AUTOSAR XML (schema 4-2-2)
package /STELLANTIS/EPT/COMSWCs
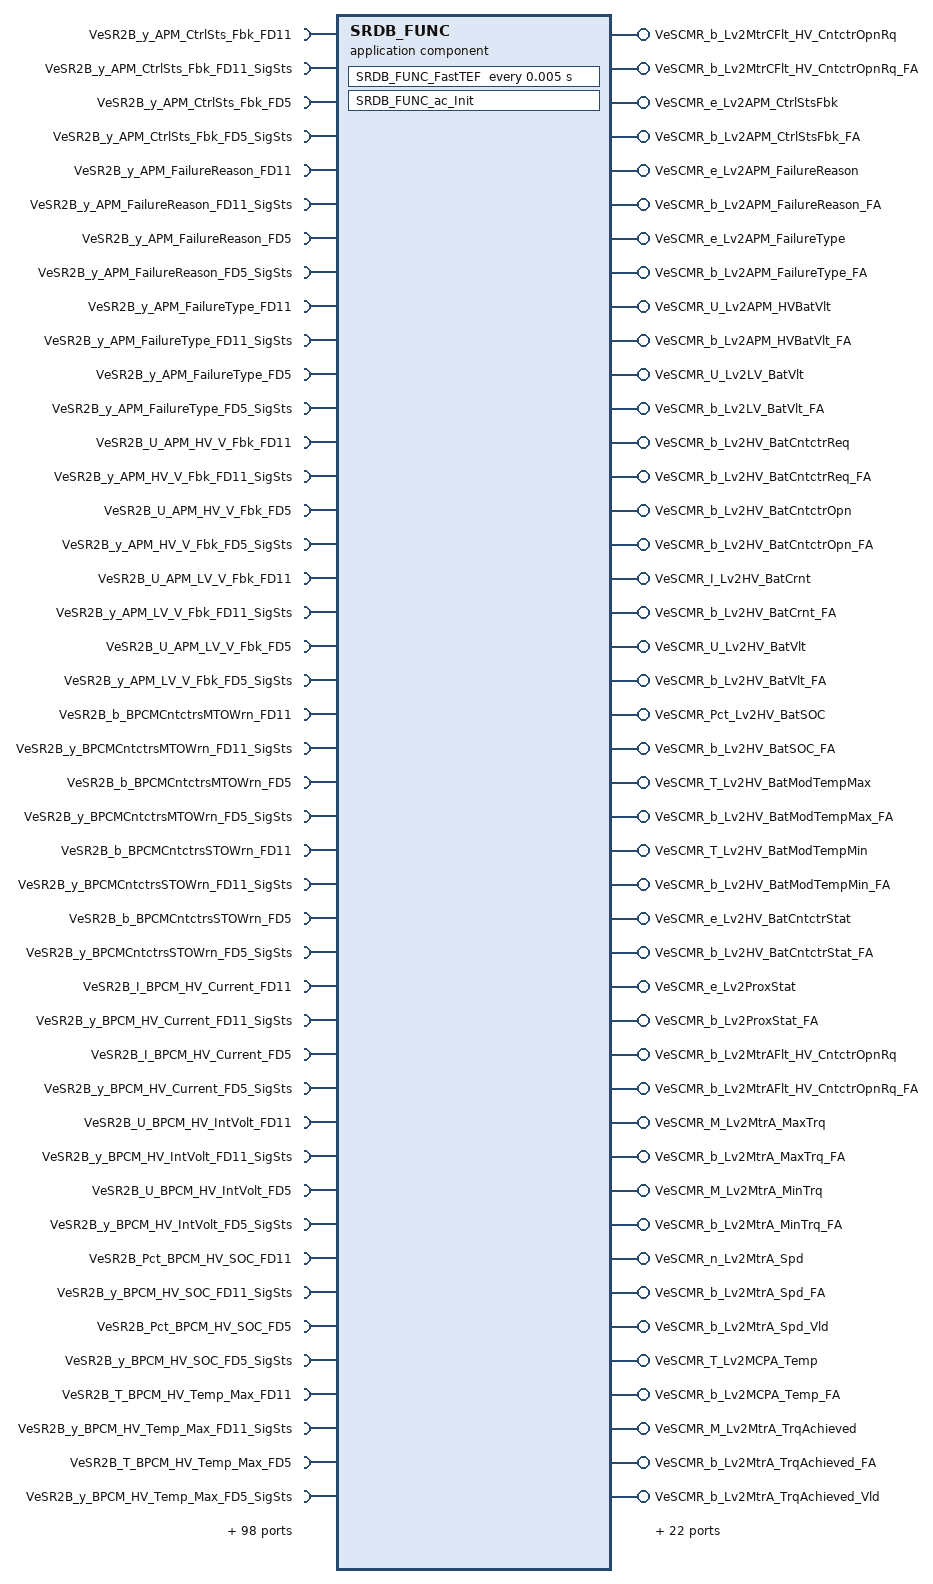
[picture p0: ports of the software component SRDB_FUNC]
  application sw component type SRDB_FUNC
    140 x require port:
      VeSR2B_y_APM_CtrlSts_Fbk_FD11: nonqueued-receiver-com-spec{data-element=Value, handle-never-received=true, init-value=0}, required-interface=VeSR2B_y_APM_CtrlSts_Fbk_FD11
      VeSR2B_y_APM_CtrlSts_Fbk_FD11_SigSts: nonqueued-receiver-com-spec{data-element=Value, init-value=0}, required-interface=VeSR2B_y_APM_CtrlSts_Fbk_FD11_SigSts
      VeSR2B_y_APM_CtrlSts_Fbk_FD5: nonqueued-receiver-com-spec{data-element=Value, handle-never-received=true, init-value=0}, required-interface=VeSR2B_y_APM_CtrlSts_Fbk_FD5
      VeSR2B_y_APM_CtrlSts_Fbk_FD5_SigSts: nonqueued-receiver-com-spec{data-element=Value, init-value=0}, required-interface=VeSR2B_y_APM_CtrlSts_Fbk_FD5_SigSts
      VeSR2B_y_APM_FailureReason_FD11: nonqueued-receiver-com-spec{data-element=Value, handle-never-received=true, init-value=0}, required-interface=VeSR2B_y_APM_FailureReason_FD11
      VeSR2B_y_APM_FailureReason_FD11_SigSts: nonqueued-receiver-com-spec{data-element=Value, init-value=0}, required-interface=VeSR2B_y_APM_FailureReason_FD11_SigSts
      VeSR2B_y_APM_FailureReason_FD5: nonqueued-receiver-com-spec{data-element=Value, handle-never-received=true, init-value=0}, required-interface=VeSR2B_y_APM_FailureReason_FD5
      VeSR2B_y_APM_FailureReason_FD5_SigSts: nonqueued-receiver-com-spec{data-element=Value, init-value=0}, required-interface=VeSR2B_y_APM_FailureReason_FD5_SigSts
      VeSR2B_y_APM_FailureType_FD11: nonqueued-receiver-com-spec{data-element=Value, handle-never-received=true, init-value=0}, required-interface=VeSR2B_y_APM_FailureType_FD11
      VeSR2B_y_APM_FailureType_FD11_SigSts: nonqueued-receiver-com-spec{data-element=Value, init-value=0}, required-interface=VeSR2B_y_APM_FailureType_FD11_SigSts
      VeSR2B_y_APM_FailureType_FD5: nonqueued-receiver-com-spec{data-element=Value, handle-never-received=true, init-value=0}, required-interface=VeSR2B_y_APM_FailureType_FD5
      VeSR2B_y_APM_FailureType_FD5_SigSts: nonqueued-receiver-com-spec{data-element=Value, init-value=0}, required-interface=VeSR2B_y_APM_FailureType_FD5_SigSts
      VeSR2B_U_APM_HV_V_Fbk_FD11: nonqueued-receiver-com-spec{data-element=Value, handle-never-received=true, init-value=0}, required-interface=VeSR2B_U_APM_HV_V_Fbk_FD11
      VeSR2B_y_APM_HV_V_Fbk_FD11_SigSts: nonqueued-receiver-com-spec{data-element=Value, init-value=0}, required-interface=VeSR2B_y_APM_HV_V_Fbk_FD11_SigSts
      VeSR2B_U_APM_HV_V_Fbk_FD5: nonqueued-receiver-com-spec{data-element=Value, handle-never-received=true, init-value=0}, required-interface=VeSR2B_U_APM_HV_V_Fbk_FD5
      VeSR2B_y_APM_HV_V_Fbk_FD5_SigSts: nonqueued-receiver-com-spec{data-element=Value, init-value=0}, required-interface=VeSR2B_y_APM_HV_V_Fbk_FD5_SigSts
      VeSR2B_U_APM_LV_V_Fbk_FD11: nonqueued-receiver-com-spec{data-element=Value, handle-never-received=true, init-value=0}, required-interface=VeSR2B_U_APM_LV_V_Fbk_FD11
      VeSR2B_y_APM_LV_V_Fbk_FD11_SigSts: nonqueued-receiver-com-spec{data-element=Value, init-value=0}, required-interface=VeSR2B_y_APM_LV_V_Fbk_FD11_SigSts
      VeSR2B_U_APM_LV_V_Fbk_FD5: nonqueued-receiver-com-spec{data-element=Value, handle-never-received=true, init-value=0}, required-interface=VeSR2B_U_APM_LV_V_Fbk_FD5
      VeSR2B_y_APM_LV_V_Fbk_FD5_SigSts: nonqueued-receiver-com-spec{data-element=Value, init-value=0}, required-interface=VeSR2B_y_APM_LV_V_Fbk_FD5_SigSts
      VeSR2B_b_BPCMCntctrsMTOWrn_FD11: nonqueued-receiver-com-spec{data-element=Value, handle-never-received=true, init-value=0}, required-interface=VeSR2B_b_BPCMCntctrsMTOWrn_FD11
      VeSR2B_y_BPCMCntctrsMTOWrn_FD11_SigSts: nonqueued-receiver-com-spec{data-element=Value, init-value=0}, required-interface=VeSR2B_y_BPCMCntctrsMTOWrn_FD11_SigSts
      VeSR2B_b_BPCMCntctrsMTOWrn_FD5: nonqueued-receiver-com-spec{data-element=Value, handle-never-received=true, init-value=0}, required-interface=VeSR2B_b_BPCMCntctrsMTOWrn_FD5
      VeSR2B_y_BPCMCntctrsMTOWrn_FD5_SigSts: nonqueued-receiver-com-spec{data-element=Value, init-value=0}, required-interface=VeSR2B_y_BPCMCntctrsMTOWrn_FD5_SigSts
      VeSR2B_b_BPCMCntctrsSTOWrn_FD11: nonqueued-receiver-com-spec{data-element=Value, handle-never-received=true, init-value=0}, required-interface=VeSR2B_b_BPCMCntctrsSTOWrn_FD11
      VeSR2B_y_BPCMCntctrsSTOWrn_FD11_SigSts: nonqueued-receiver-com-spec{data-element=Value, init-value=0}, required-interface=VeSR2B_y_BPCMCntctrsSTOWrn_FD11_SigSts
      VeSR2B_b_BPCMCntctrsSTOWrn_FD5: nonqueued-receiver-com-spec{data-element=Value, handle-never-received=true, init-value=0}, required-interface=VeSR2B_b_BPCMCntctrsSTOWrn_FD5
      VeSR2B_y_BPCMCntctrsSTOWrn_FD5_SigSts: nonqueued-receiver-com-spec{data-element=Value, init-value=0}, required-interface=VeSR2B_y_BPCMCntctrsSTOWrn_FD5_SigSts
      VeSR2B_I_BPCM_HV_Current_FD11: nonqueued-receiver-com-spec{data-element=Value, handle-never-received=true, init-value=0}, required-interface=VeSR2B_I_BPCM_HV_Current_FD11
      VeSR2B_y_BPCM_HV_Current_FD11_SigSts: nonqueued-receiver-com-spec{data-element=Value, init-value=0}, required-interface=VeSR2B_y_BPCM_HV_Current_FD11_SigSts
      VeSR2B_I_BPCM_HV_Current_FD5: nonqueued-receiver-com-spec{data-element=Value, handle-never-received=true, init-value=0}, required-interface=VeSR2B_I_BPCM_HV_Current_FD5
      VeSR2B_y_BPCM_HV_Current_FD5_SigSts: nonqueued-receiver-com-spec{data-element=Value, init-value=0}, required-interface=VeSR2B_y_BPCM_HV_Current_FD5_SigSts
      VeSR2B_U_BPCM_HV_IntVolt_FD11: nonqueued-receiver-com-spec{data-element=Value, handle-never-received=true, init-value=0}, required-interface=VeSR2B_U_BPCM_HV_IntVolt_FD11
      VeSR2B_y_BPCM_HV_IntVolt_FD11_SigSts: nonqueued-receiver-com-spec{data-element=Value, init-value=0}, required-interface=VeSR2B_y_BPCM_HV_IntVolt_FD11_SigSts
      VeSR2B_U_BPCM_HV_IntVolt_FD5: nonqueued-receiver-com-spec{data-element=Value, handle-never-received=true, init-value=0}, required-interface=VeSR2B_U_BPCM_HV_IntVolt_FD5
      VeSR2B_y_BPCM_HV_IntVolt_FD5_SigSts: nonqueued-receiver-com-spec{data-element=Value, init-value=0}, required-interface=VeSR2B_y_BPCM_HV_IntVolt_FD5_SigSts
      VeSR2B_Pct_BPCM_HV_SOC_FD11: nonqueued-receiver-com-spec{data-element=Value, handle-never-received=true, init-value=0}, required-interface=VeSR2B_Pct_BPCM_HV_SOC_FD11
      VeSR2B_y_BPCM_HV_SOC_FD11_SigSts: nonqueued-receiver-com-spec{data-element=Value, init-value=0}, required-interface=VeSR2B_y_BPCM_HV_SOC_FD11_SigSts
      VeSR2B_Pct_BPCM_HV_SOC_FD5: nonqueued-receiver-com-spec{data-element=Value, handle-never-received=true, init-value=0}, required-interface=VeSR2B_Pct_BPCM_HV_SOC_FD5
      VeSR2B_y_BPCM_HV_SOC_FD5_SigSts: nonqueued-receiver-com-spec{data-element=Value, init-value=0}, required-interface=VeSR2B_y_BPCM_HV_SOC_FD5_SigSts
      VeSR2B_T_BPCM_HV_Temp_Max_FD11: nonqueued-receiver-com-spec{data-element=Value, handle-never-received=true, init-value=0}, required-interface=VeSR2B_T_BPCM_HV_Temp_Max_FD11
      VeSR2B_y_BPCM_HV_Temp_Max_FD11_SigSts: nonqueued-receiver-com-spec{data-element=Value, init-value=0}, required-interface=VeSR2B_y_BPCM_HV_Temp_Max_FD11_SigSts
      VeSR2B_T_BPCM_HV_Temp_Max_FD5: nonqueued-receiver-com-spec{data-element=Value, handle-never-received=true, init-value=0}, required-interface=VeSR2B_T_BPCM_HV_Temp_Max_FD5
      VeSR2B_y_BPCM_HV_Temp_Max_FD5_SigSts: nonqueued-receiver-com-spec{data-element=Value, init-value=0}, required-interface=VeSR2B_y_BPCM_HV_Temp_Max_FD5_SigSts
      VeSR2B_T_BPCM_HV_Temp_Min_FD11: nonqueued-receiver-com-spec{data-element=Value, handle-never-received=true, init-value=0}, required-interface=VeSR2B_T_BPCM_HV_Temp_Min_FD11
      VeSR2B_y_BPCM_HV_Temp_Min_FD11_SigSts: nonqueued-receiver-com-spec{data-element=Value, init-value=0}, required-interface=VeSR2B_y_BPCM_HV_Temp_Min_FD11_SigSts
      VeSR2B_T_BPCM_HV_Temp_Min_FD5: nonqueued-receiver-com-spec{data-element=Value, handle-never-received=true, init-value=0}, required-interface=VeSR2B_T_BPCM_HV_Temp_Min_FD5
      VeSR2B_y_BPCM_HV_Temp_Min_FD5_SigSts: nonqueued-receiver-com-spec{data-element=Value, init-value=0}, required-interface=VeSR2B_y_BPCM_HV_Temp_Min_FD5_SigSts
      VeSR2B_y_BPCM_HV_TracBusStsFD11: nonqueued-receiver-com-spec{data-element=Value, handle-never-received=true, init-value=0}, required-interface=VeSR2B_y_BPCM_HV_TracBusStsFD11
      VeSR2B_y_BPCM_HV_TracBusStsFD11_SigSts: nonqueued-receiver-com-spec{data-element=Value, init-value=0}, required-interface=VeSR2B_y_BPCM_HV_TracBusStsFD11_SigSts
      VeSR2B_y_BPCM_HV_TracBusStsFD5: nonqueued-receiver-com-spec{data-element=Value, handle-never-received=true, init-value=0}, required-interface=VeSR2B_y_BPCM_HV_TracBusStsFD5
      VeSR2B_y_BPCM_HV_TracBusStsFD5_SigSts: nonqueued-receiver-com-spec{data-element=Value, init-value=0}, required-interface=VeSR2B_y_BPCM_HV_TracBusStsFD5_SigSts
      VeSR2B_y_ProximitySts_FD11: nonqueued-receiver-com-spec{data-element=Value, handle-never-received=true, init-value=0}, required-interface=VeSR2B_y_ProximitySts_FD11
      VeSR2B_y_ProximitySts_FD11_SigSts: nonqueued-receiver-com-spec{data-element=Value, init-value=0}, required-interface=VeSR2B_y_ProximitySts_FD11_SigSts
      VeSR2B_y_ProximitySts_FD5: nonqueued-receiver-com-spec{data-element=Value, handle-never-received=true, init-value=0}, required-interface=VeSR2B_y_ProximitySts_FD5
      VeSR2B_y_ProximitySts_FD5_SigSts: nonqueued-receiver-com-spec{data-element=Value, init-value=0}, required-interface=VeSR2B_y_ProximitySts_FD5_SigSts
      VeSR2B_b_MCPA_HV_CnctrOpn_Req_P_FD16: nonqueued-receiver-com-spec{data-element=Value, handle-never-received=true, init-value=0}, required-interface=VeSR2B_b_MCPA_HV_CnctrOpn_Req_P_FD16
      VeSR2B_y_MCPA_HV_CnctrOpn_Req_P_FD16_SigSts: nonqueued-receiver-com-spec{data-element=Value, init-value=0}, required-interface=VeSR2B_y_MCPA_HV_CnctrOpn_Req_P_FD16_SigSts
      VeSR2B_b_MCPA_HV_CnctrOpnRqPFD5: nonqueued-receiver-com-spec{data-element=Value, handle-never-received=true, init-value=0}, required-interface=VeSR2B_b_MCPA_HV_CnctrOpnRqPFD5
      VeSR2B_y_MCPA_HV_CnctrOpnRqPFD5_SigSts: nonqueued-receiver-com-spec{data-element=Value, init-value=0}, required-interface=VeSR2B_y_MCPA_HV_CnctrOpnRqPFD5_SigSts
      VeSR2B_M_MCPA_MaxTorq_P_FD16: nonqueued-receiver-com-spec{data-element=Value, handle-never-received=true, init-value=0}, required-interface=VeSR2B_M_MCPA_MaxTorq_P_FD16
      VeSR2B_y_MCPA_MaxTorq_P_FD16_SigSts: nonqueued-receiver-com-spec{data-element=Value, init-value=0}, required-interface=VeSR2B_y_MCPA_MaxTorq_P_FD16_SigSts
      VeSR2B_M_MCPA_MaxTorq_P_FD5: nonqueued-receiver-com-spec{data-element=Value, handle-never-received=true, init-value=0}, required-interface=VeSR2B_M_MCPA_MaxTorq_P_FD5
      VeSR2B_y_MCPA_MaxTorq_P_FD5_SigSts: nonqueued-receiver-com-spec{data-element=Value, init-value=0}, required-interface=VeSR2B_y_MCPA_MaxTorq_P_FD5_SigSts
      VeSR2B_M_MCPA_MinTorq_P_FD16: nonqueued-receiver-com-spec{data-element=Value, handle-never-received=true, init-value=0}, required-interface=VeSR2B_M_MCPA_MinTorq_P_FD16
      VeSR2B_y_MCPA_MinTorq_P_FD16_SigSts: nonqueued-receiver-com-spec{data-element=Value, init-value=0}, required-interface=VeSR2B_y_MCPA_MinTorq_P_FD16_SigSts
      VeSR2B_M_MCPA_MinTorq_P_FD5: nonqueued-receiver-com-spec{data-element=Value, handle-never-received=true, init-value=0}, required-interface=VeSR2B_M_MCPA_MinTorq_P_FD5
      VeSR2B_y_MCPA_MinTorq_P_FD5_SigSts: nonqueued-receiver-com-spec{data-element=Value, init-value=0}, required-interface=VeSR2B_y_MCPA_MinTorq_P_FD5_SigSts
      VeSR2B_n_MCPA_RPM_P_FD16: nonqueued-receiver-com-spec{data-element=Value, handle-never-received=true, init-value=0}, required-interface=VeSR2B_n_MCPA_RPM_P_FD16
      VeSR2B_y_MCPA_RPM_P_FD16_SigSts: nonqueued-receiver-com-spec{data-element=Value, init-value=0}, required-interface=VeSR2B_y_MCPA_RPM_P_FD16_SigSts
      VeSR2B_n_MCPA_RPM_P_FD5: nonqueued-receiver-com-spec{data-element=Value, handle-never-received=true, init-value=0}, required-interface=VeSR2B_n_MCPA_RPM_P_FD5
      VeSR2B_y_MCPA_RPM_P_FD5_SigSts: nonqueued-receiver-com-spec{data-element=Value, init-value=0}, required-interface=VeSR2B_y_MCPA_RPM_P_FD5_SigSts
      VeSR2B_b_MCPA_RPM_V_P_FD16: nonqueued-receiver-com-spec{data-element=Value, handle-never-received=true, init-value=0}, required-interface=VeSR2B_b_MCPA_RPM_V_P_FD16
      VeSR2B_y_MCPA_RPM_V_P_FD16_SigSts: nonqueued-receiver-com-spec{data-element=Value, init-value=0}, required-interface=VeSR2B_y_MCPA_RPM_V_P_FD16_SigSts
      VeSR2B_b_MCPA_RPM_V_P_FD5: nonqueued-receiver-com-spec{data-element=Value, handle-never-received=true, init-value=0}, required-interface=VeSR2B_b_MCPA_RPM_V_P_FD5
      VeSR2B_y_MCPA_RPM_V_P_FD5_SigSts: nonqueued-receiver-com-spec{data-element=Value, init-value=0}, required-interface=VeSR2B_y_MCPA_RPM_V_P_FD5_SigSts
      VeSR2B_T_MCPA_Temp_P_FD16: nonqueued-receiver-com-spec{data-element=Value, handle-never-received=true, init-value=0}, required-interface=VeSR2B_T_MCPA_Temp_P_FD16
      VeSR2B_y_MCPA_Temp_P_FD16_SigSts: nonqueued-receiver-com-spec{data-element=Value, init-value=0}, required-interface=VeSR2B_y_MCPA_Temp_P_FD16_SigSts
      VeSR2B_T_MCPA_Temp_P_FD5: nonqueued-receiver-com-spec{data-element=Value, handle-never-received=true, init-value=0}, required-interface=VeSR2B_T_MCPA_Temp_P_FD5
      VeSR2B_y_MCPA_Temp_P_FD5_SigSts: nonqueued-receiver-com-spec{data-element=Value, init-value=0}, required-interface=VeSR2B_y_MCPA_Temp_P_FD5_SigSts
      VeSR2B_M_MCPA_TorqAchved_AEMD_P_FD16: nonqueued-receiver-com-spec{data-element=Value, handle-never-received=true, init-value=0}, required-interface=VeSR2B_M_MCPA_TorqAchved_AEMD_P_FD16
      VeSR2B_y_MCPA_TorqAchved_AEMD_P_FD16_SigSts: nonqueued-receiver-com-spec{data-element=Value, init-value=0}, required-interface=VeSR2B_y_MCPA_TorqAchved_AEMD_P_FD16_SigSts
      VeSR2B_M_MCPA_TrqAchvdAEMDPFD5: nonqueued-receiver-com-spec{data-element=Value, handle-never-received=true, init-value=0}, required-interface=VeSR2B_M_MCPA_TrqAchvdAEMDPFD5
      VeSR2B_y_MCPA_TrqAchvdAEMDPFD5_SigSts: nonqueued-receiver-com-spec{data-element=Value, init-value=0}, required-interface=VeSR2B_y_MCPA_TrqAchvdAEMDPFD5_SigSts
      VeSR2B_b_MCPA_TrqAchvd_AEMD_V_P_FD16: nonqueued-receiver-com-spec{data-element=Value, handle-never-received=true, init-value=0}, required-interface=VeSR2B_b_MCPA_TrqAchvd_AEMD_V_P_FD16
      VeSR2B_y_MCPA_TrqAchvd_AEMD_V_P_FD16_SigSts: nonqueued-receiver-com-spec{data-element=Value, init-value=0}, required-interface=VeSR2B_y_MCPA_TrqAchvd_AEMD_V_P_FD16_SigSts
      VeSR2B_b_MCPA_TrqAchvdAEMDVPFD5: nonqueued-receiver-com-spec{data-element=Value, handle-never-received=true, init-value=0}, required-interface=VeSR2B_b_MCPA_TrqAchvdAEMDVPFD5
      VeSR2B_y_MCPA_TrqAchvdAEMDVPFD5_SigSts: nonqueued-receiver-com-spec{data-element=Value, init-value=0}, required-interface=VeSR2B_y_MCPA_TrqAchvdAEMDVPFD5_SigSts
      VeSR2B_M_MCPA_Torque_Achieved_P_FD16: nonqueued-receiver-com-spec{data-element=Value, handle-never-received=true, init-value=0}, required-interface=VeSR2B_M_MCPA_Torque_Achieved_P_FD16
      VeSR2B_y_MCPA_Torque_Achieved_P_FD16_SigSts: nonqueued-receiver-com-spec{data-element=Value, init-value=0}, required-interface=VeSR2B_y_MCPA_Torque_Achieved_P_FD16_SigSts
      VeSR2B_M_MCPA_Torque_AchvdPFD5: nonqueued-receiver-com-spec{data-element=Value, handle-never-received=true, init-value=0}, required-interface=VeSR2B_M_MCPA_Torque_AchvdPFD5
      VeSR2B_y_MCPA_Torque_AchvdPFD5_SigSts: nonqueued-receiver-com-spec{data-element=Value, init-value=0}, required-interface=VeSR2B_y_MCPA_Torque_AchvdPFD5_SigSts
      VeSR2B_b_MCPA_Torque_Achved_V_P_FD16: nonqueued-receiver-com-spec{data-element=Value, handle-never-received=true, init-value=0}, required-interface=VeSR2B_b_MCPA_Torque_Achved_V_P_FD16
      VeSR2B_y_MCPA_Torque_Achved_V_P_FD16_SigSts: nonqueued-receiver-com-spec{data-element=Value, init-value=0}, required-interface=VeSR2B_y_MCPA_Torque_Achved_V_P_FD16_SigSts
      VeSR2B_b_MCPA_Trque_AchvdVPFD5: nonqueued-receiver-com-spec{data-element=Value, handle-never-received=true, init-value=0}, required-interface=VeSR2B_b_MCPA_Trque_AchvdVPFD5
      VeSR2B_y_MCPA_Trque_AchvdVPFD5_SigSts: nonqueued-receiver-com-spec{data-element=Value, init-value=0}, required-interface=VeSR2B_y_MCPA_Trque_AchvdVPFD5_SigSts
      VeSR2B_b_MCPB_HV_CnctrOpn_Req_P_FD16: nonqueued-receiver-com-spec{data-element=Value, handle-never-received=true, init-value=0}, required-interface=VeSR2B_b_MCPB_HV_CnctrOpn_Req_P_FD16
      VeSR2B_y_MCPB_HV_CnctrOpn_Req_P_FD16_SigSts: nonqueued-receiver-com-spec{data-element=Value, init-value=0}, required-interface=VeSR2B_y_MCPB_HV_CnctrOpn_Req_P_FD16_SigSts
      VeSR2B_b_MCPB_HV_CnctrOpnRqPFD5: nonqueued-receiver-com-spec{data-element=Value, handle-never-received=true, init-value=0}, required-interface=VeSR2B_b_MCPB_HV_CnctrOpnRqPFD5
      VeSR2B_y_MCPB_HV_CnctrOpnRqPFD5_SigSts: nonqueued-receiver-com-spec{data-element=Value, init-value=0}, required-interface=VeSR2B_y_MCPB_HV_CnctrOpnRqPFD5_SigSts
      VeSR2B_M_MCPB_MaxTorq_P_FD16: nonqueued-receiver-com-spec{data-element=Value, handle-never-received=true, init-value=0}, required-interface=VeSR2B_M_MCPB_MaxTorq_P_FD16
      VeSR2B_y_MCPB_MaxTorq_P_FD16_SigSts: nonqueued-receiver-com-spec{data-element=Value, init-value=0}, required-interface=VeSR2B_y_MCPB_MaxTorq_P_FD16_SigSts
      VeSR2B_M_MCPB_MaxTorq_P_FD5: nonqueued-receiver-com-spec{data-element=Value, handle-never-received=true, init-value=0}, required-interface=VeSR2B_M_MCPB_MaxTorq_P_FD5
      VeSR2B_y_MCPB_MaxTorq_P_FD5_SigSts: nonqueued-receiver-com-spec{data-element=Value, init-value=0}, required-interface=VeSR2B_y_MCPB_MaxTorq_P_FD5_SigSts
      VeSR2B_M_MCPB_MinTorq_P_FD16: nonqueued-receiver-com-spec{data-element=Value, handle-never-received=true, init-value=0}, required-interface=VeSR2B_M_MCPB_MinTorq_P_FD16
      VeSR2B_y_MCPB_MinTorq_P_FD16_SigSts: nonqueued-receiver-com-spec{data-element=Value, init-value=0}, required-interface=VeSR2B_y_MCPB_MinTorq_P_FD16_SigSts
      VeSR2B_M_MCPB_MinTorq_P_FD5: nonqueued-receiver-com-spec{data-element=Value, handle-never-received=true, init-value=0}, required-interface=VeSR2B_M_MCPB_MinTorq_P_FD5
      VeSR2B_y_MCPB_MinTorq_P_FD5_SigSts: nonqueued-receiver-com-spec{data-element=Value, init-value=0}, required-interface=VeSR2B_y_MCPB_MinTorq_P_FD5_SigSts
      VeSR2B_y_MCPB_MtrIndex_P_FD16: nonqueued-receiver-com-spec{data-element=Value, handle-never-received=true, init-value=0}, required-interface=VeSR2B_y_MCPB_MtrIndex_P_FD16
      VeSR2B_y_MCPB_MtrIndex_P_FD16_SigSts: nonqueued-receiver-com-spec{data-element=Value, init-value=0}, required-interface=VeSR2B_y_MCPB_MtrIndex_P_FD16_SigSts
      VeSR2B_y_MCPB_MtrIndex_P_FD5: nonqueued-receiver-com-spec{data-element=Value, handle-never-received=true, init-value=0}, required-interface=VeSR2B_y_MCPB_MtrIndex_P_FD5
      VeSR2B_y_MCPB_MtrIndex_P_FD5_SigSts: nonqueued-receiver-com-spec{data-element=Value, init-value=0}, required-interface=VeSR2B_y_MCPB_MtrIndex_P_FD5_SigSts
      VeSR2B_n_MCPB_RPM_P_FD16: nonqueued-receiver-com-spec{data-element=Value, handle-never-received=true, init-value=0}, required-interface=VeSR2B_n_MCPB_RPM_P_FD16
      VeSR2B_y_MCPB_RPM_P_FD16_SigSts: nonqueued-receiver-com-spec{data-element=Value, init-value=0}, required-interface=VeSR2B_y_MCPB_RPM_P_FD16_SigSts
      VeSR2B_n_MCPB_RPM_P_FD5: nonqueued-receiver-com-spec{data-element=Value, handle-never-received=true, init-value=0}, required-interface=VeSR2B_n_MCPB_RPM_P_FD5
      VeSR2B_y_MCPB_RPM_P_FD5_SigSts: nonqueued-receiver-com-spec{data-element=Value, init-value=0}, required-interface=VeSR2B_y_MCPB_RPM_P_FD5_SigSts
      VeSR2B_b_MCPB_RPM_V_P_FD16: nonqueued-receiver-com-spec{data-element=Value, handle-never-received=true, init-value=0}, required-interface=VeSR2B_b_MCPB_RPM_V_P_FD16
      VeSR2B_y_MCPB_RPM_V_P_FD16_SigSts: nonqueued-receiver-com-spec{data-element=Value, init-value=0}, required-interface=VeSR2B_y_MCPB_RPM_V_P_FD16_SigSts
      VeSR2B_b_MCPB_RPM_V_P_FD5: nonqueued-receiver-com-spec{data-element=Value, handle-never-received=true, init-value=0}, required-interface=VeSR2B_b_MCPB_RPM_V_P_FD5
      VeSR2B_y_MCPB_RPM_V_P_FD5_SigSts: nonqueued-receiver-com-spec{data-element=Value, init-value=0}, required-interface=VeSR2B_y_MCPB_RPM_V_P_FD5_SigSts
      VeSR2B_y_MCPB_Temp_P_FD16: nonqueued-receiver-com-spec{data-element=Value, handle-never-received=true, init-value=0}, required-interface=VeSR2B_y_MCPB_Temp_P_FD16
      VeSR2B_y_MCPB_Temp_P_FD16_SigSts: nonqueued-receiver-com-spec{data-element=Value, init-value=0}, required-interface=VeSR2B_y_MCPB_Temp_P_FD16_SigSts
      VeSR2B_y_MCPB_Temp_P_FD5: nonqueued-receiver-com-spec{data-element=Value, handle-never-received=true, init-value=0}, required-interface=VeSR2B_y_MCPB_Temp_P_FD5
      VeSR2B_y_MCPB_Temp_P_FD5_SigSts: nonqueued-receiver-com-spec{data-element=Value, init-value=0}, required-interface=VeSR2B_y_MCPB_Temp_P_FD5_SigSts
      VeSR2B_M_MCPB_TorqAchved_AEMD_P_FD16: nonqueued-receiver-com-spec{data-element=Value, handle-never-received=true, init-value=0}, required-interface=VeSR2B_M_MCPB_TorqAchved_AEMD_P_FD16
      VeSR2B_y_MCPB_TorqAchved_AEMD_P_FD16_SigSts: nonqueued-receiver-com-spec{data-element=Value, init-value=0}, required-interface=VeSR2B_y_MCPB_TorqAchved_AEMD_P_FD16_SigSts
      VeSR2B_M_MCPB_TrqAchvd_AEMDPFD5: nonqueued-receiver-com-spec{data-element=Value, handle-never-received=true, init-value=0}, required-interface=VeSR2B_M_MCPB_TrqAchvd_AEMDPFD5
      VeSR2B_y_MCPB_TrqAchvd_AEMDPFD5_SigSts: nonqueued-receiver-com-spec{data-element=Value, init-value=0}, required-interface=VeSR2B_y_MCPB_TrqAchvd_AEMDPFD5_SigSts
      VeSR2B_b_MCPB_TrqAchvd_AEMD_V_P_FD16: nonqueued-receiver-com-spec{data-element=Value, handle-never-received=true, init-value=0}, required-interface=VeSR2B_b_MCPB_TrqAchvd_AEMD_V_P_FD16
      VeSR2B_y_MCPB_TrqAchvd_AEMD_V_P_FD16_SigSts: nonqueued-receiver-com-spec{data-element=Value, init-value=0}, required-interface=VeSR2B_y_MCPB_TrqAchvd_AEMD_V_P_FD16_SigSts
      VeSR2B_b_MCPB_TrqAchvdAEMDVPFD5: nonqueued-receiver-com-spec{data-element=Value, handle-never-received=true, init-value=0}, required-interface=VeSR2B_b_MCPB_TrqAchvdAEMDVPFD5
      VeSR2B_y_MCPB_TrqAchvdAEMDVPFD5_SigSts: nonqueued-receiver-com-spec{data-element=Value, init-value=0}, required-interface=VeSR2B_y_MCPB_TrqAchvdAEMDVPFD5_SigSts
      VeSR2B_M_MCPB_Torque_Achieved_P_FD16: nonqueued-receiver-com-spec{data-element=Value, handle-never-received=true, init-value=0}, required-interface=VeSR2B_M_MCPB_Torque_Achieved_P_FD16
      VeSR2B_y_MCPB_Torque_Achieved_P_FD16_SigSts: nonqueued-receiver-com-spec{data-element=Value, init-value=0}, required-interface=VeSR2B_y_MCPB_Torque_Achieved_P_FD16_SigSts
      VeSR2B_M_MCPB_Trq_Achved_P_FD5: nonqueued-receiver-com-spec{data-element=Value, handle-never-received=true, init-value=0}, required-interface=VeSR2B_M_MCPB_Trq_Achved_P_FD5
      VeSR2B_y_MCPB_Trq_Achved_P_FD5_SigSts: nonqueued-receiver-com-spec{data-element=Value, init-value=0}, required-interface=VeSR2B_y_MCPB_Trq_Achved_P_FD5_SigSts
      VeSR2B_b_MCPB_Torque_Achved_V_P_FD16: nonqueued-receiver-com-spec{data-element=Value, handle-never-received=true, init-value=0}, required-interface=VeSR2B_b_MCPB_Torque_Achved_V_P_FD16
      VeSR2B_y_MCPB_Torque_Achved_V_P_FD16_SigSts: nonqueued-receiver-com-spec{data-element=Value, init-value=0}, required-interface=VeSR2B_y_MCPB_Torque_Achved_V_P_FD16_SigSts
      VeSR2B_b_MCPB_Trq_Achved_V_PFD5: nonqueued-receiver-com-spec{data-element=Value, handle-never-received=true, init-value=0}, required-interface=VeSR2B_b_MCPB_Trq_Achved_V_PFD5
      VeSR2B_y_MCPB_Trq_Achved_V_PFD5_SigSts: nonqueued-receiver-com-spec{data-element=Value, init-value=0}, required-interface=VeSR2B_y_MCPB_Trq_Achved_V_PFD5_SigSts
    66 x provide port:
      VeSCMR_b_Lv2MtrCFlt_HV_CntctrOpnRq: nonqueued-sender-com-spec{data-element=Value, init-value=0}, provided-interface=VeSCMR_b_Lv2MtrCFlt_HV_CntctrOpnRq
      VeSCMR_b_Lv2MtrCFlt_HV_CntctrOpnRq_FA: nonqueued-sender-com-spec{data-element=Value, init-value=0}, provided-interface=VeSCMR_b_Lv2MtrCFlt_HV_CntctrOpnRq_FA
      VeSCMR_e_Lv2APM_CtrlStsFbk: nonqueued-sender-com-spec{data-element=Value, init-value=0}, provided-interface=VeSCMR_e_Lv2APM_CtrlStsFbk
      VeSCMR_b_Lv2APM_CtrlStsFbk_FA: nonqueued-sender-com-spec{data-element=Value, init-value=0}, provided-interface=VeSCMR_b_Lv2APM_CtrlStsFbk_FA
      VeSCMR_e_Lv2APM_FailureReason: nonqueued-sender-com-spec{data-element=Value, init-value=0}, provided-interface=VeSCMR_e_Lv2APM_FailureReason
      VeSCMR_b_Lv2APM_FailureReason_FA: nonqueued-sender-com-spec{data-element=Value, init-value=0}, provided-interface=VeSCMR_b_Lv2APM_FailureReason_FA
      VeSCMR_e_Lv2APM_FailureType: nonqueued-sender-com-spec{data-element=Value, init-value=0}, provided-interface=VeSCMR_e_Lv2APM_FailureType
      VeSCMR_b_Lv2APM_FailureType_FA: nonqueued-sender-com-spec{data-element=Value, init-value=0}, provided-interface=VeSCMR_b_Lv2APM_FailureType_FA
      VeSCMR_U_Lv2APM_HVBatVlt: nonqueued-sender-com-spec{data-element=Value, init-value=0}, provided-interface=VeSCMR_U_Lv2APM_HVBatVlt
      VeSCMR_b_Lv2APM_HVBatVlt_FA: nonqueued-sender-com-spec{data-element=Value, init-value=0}, provided-interface=VeSCMR_b_Lv2APM_HVBatVlt_FA
      VeSCMR_U_Lv2LV_BatVlt: nonqueued-sender-com-spec{data-element=Value, init-value=0}, provided-interface=VeSCMR_U_Lv2LV_BatVlt
      VeSCMR_b_Lv2LV_BatVlt_FA: nonqueued-sender-com-spec{data-element=Value, init-value=0}, provided-interface=VeSCMR_b_Lv2LV_BatVlt_FA
      VeSCMR_b_Lv2HV_BatCntctrReq: nonqueued-sender-com-spec{data-element=Value, init-value=0}, provided-interface=VeSCMR_b_Lv2HV_BatCntctrReq
      VeSCMR_b_Lv2HV_BatCntctrReq_FA: nonqueued-sender-com-spec{data-element=Value, init-value=0}, provided-interface=VeSCMR_b_Lv2HV_BatCntctrReq_FA
      VeSCMR_b_Lv2HV_BatCntctrOpn: nonqueued-sender-com-spec{data-element=Value, init-value=0}, provided-interface=VeSCMR_b_Lv2HV_BatCntctrOpn
      VeSCMR_b_Lv2HV_BatCntctrOpn_FA: nonqueued-sender-com-spec{data-element=Value, init-value=0}, provided-interface=VeSCMR_b_Lv2HV_BatCntctrOpn_FA
      VeSCMR_I_Lv2HV_BatCrnt: nonqueued-sender-com-spec{data-element=Value, init-value=0}, provided-interface=VeSCMR_I_Lv2HV_BatCrnt
      VeSCMR_b_Lv2HV_BatCrnt_FA: nonqueued-sender-com-spec{data-element=Value, init-value=0}, provided-interface=VeSCMR_b_Lv2HV_BatCrnt_FA
      VeSCMR_U_Lv2HV_BatVlt: nonqueued-sender-com-spec{data-element=Value, init-value=0}, provided-interface=VeSCMR_U_Lv2HV_BatVlt
      VeSCMR_b_Lv2HV_BatVlt_FA: nonqueued-sender-com-spec{data-element=Value, init-value=0}, provided-interface=VeSCMR_b_Lv2HV_BatVlt_FA
      VeSCMR_Pct_Lv2HV_BatSOC: nonqueued-sender-com-spec{data-element=Value, init-value=0}, provided-interface=VeSCMR_Pct_Lv2HV_BatSOC
      VeSCMR_b_Lv2HV_BatSOC_FA: nonqueued-sender-com-spec{data-element=Value, init-value=0}, provided-interface=VeSCMR_b_Lv2HV_BatSOC_FA
      VeSCMR_T_Lv2HV_BatModTempMax: nonqueued-sender-com-spec{data-element=Value, init-value=0}, provided-interface=VeSCMR_T_Lv2HV_BatModTempMax
      VeSCMR_b_Lv2HV_BatModTempMax_FA: nonqueued-sender-com-spec{data-element=Value, init-value=0}, provided-interface=VeSCMR_b_Lv2HV_BatModTempMax_FA
      VeSCMR_T_Lv2HV_BatModTempMin: nonqueued-sender-com-spec{data-element=Value, init-value=0}, provided-interface=VeSCMR_T_Lv2HV_BatModTempMin
      VeSCMR_b_Lv2HV_BatModTempMin_FA: nonqueued-sender-com-spec{data-element=Value, init-value=0}, provided-interface=VeSCMR_b_Lv2HV_BatModTempMin_FA
      VeSCMR_e_Lv2HV_BatCntctrStat: nonqueued-sender-com-spec{data-element=Value, init-value=0}, provided-interface=VeSCMR_e_Lv2HV_BatCntctrStat
      VeSCMR_b_Lv2HV_BatCntctrStat_FA: nonqueued-sender-com-spec{data-element=Value, init-value=0}, provided-interface=VeSCMR_b_Lv2HV_BatCntctrStat_FA
      VeSCMR_e_Lv2ProxStat: nonqueued-sender-com-spec{data-element=Value, init-value=CeGSMR_e_Prox_Lo}, provided-interface=VeSCMR_e_Lv2ProxStat
      VeSCMR_b_Lv2ProxStat_FA: nonqueued-sender-com-spec{data-element=Value, init-value=0}, provided-interface=VeSCMR_b_Lv2ProxStat_FA
      VeSCMR_b_Lv2MtrAFlt_HV_CntctrOpnRq: nonqueued-sender-com-spec{data-element=Value, init-value=0}, provided-interface=VeSCMR_b_Lv2MtrAFlt_HV_CntctrOpnRq
      VeSCMR_b_Lv2MtrAFlt_HV_CntctrOpnRq_FA: nonqueued-sender-com-spec{data-element=Value, init-value=0}, provided-interface=VeSCMR_b_Lv2MtrAFlt_HV_CntctrOpnRq_FA
      VeSCMR_M_Lv2MtrA_MaxTrq: nonqueued-sender-com-spec{data-element=Value, init-value=0}, provided-interface=VeSCMR_M_Lv2MtrA_MaxTrq
      VeSCMR_b_Lv2MtrA_MaxTrq_FA: nonqueued-sender-com-spec{data-element=Value, init-value=0}, provided-interface=VeSCMR_b_Lv2MtrA_MaxTrq_FA
      VeSCMR_M_Lv2MtrA_MinTrq: nonqueued-sender-com-spec{data-element=Value, init-value=0}, provided-interface=VeSCMR_M_Lv2MtrA_MinTrq
      VeSCMR_b_Lv2MtrA_MinTrq_FA: nonqueued-sender-com-spec{data-element=Value, init-value=0}, provided-interface=VeSCMR_b_Lv2MtrA_MinTrq_FA
      VeSCMR_n_Lv2MtrA_Spd: nonqueued-sender-com-spec{data-element=Value, init-value=0}, provided-interface=VeSCMR_n_Lv2MtrA_Spd
      VeSCMR_b_Lv2MtrA_Spd_FA: nonqueued-sender-com-spec{data-element=Value, init-value=0}, provided-interface=VeSCMR_b_Lv2MtrA_Spd_FA
      VeSCMR_b_Lv2MtrA_Spd_Vld: nonqueued-sender-com-spec{data-element=Value, init-value=0}, provided-interface=VeSCMR_b_Lv2MtrA_Spd_Vld
      VeSCMR_T_Lv2MCPA_Temp: nonqueued-sender-com-spec{data-element=Value, init-value=0}, provided-interface=VeSCMR_T_Lv2MCPA_Temp
      VeSCMR_b_Lv2MCPA_Temp_FA: nonqueued-sender-com-spec{data-element=Value, init-value=0}, provided-interface=VeSCMR_b_Lv2MCPA_Temp_FA
      VeSCMR_M_Lv2MtrA_TrqAchieved: nonqueued-sender-com-spec{data-element=Value, init-value=0}, provided-interface=VeSCMR_M_Lv2MtrA_TrqAchieved
      VeSCMR_b_Lv2MtrA_TrqAchieved_FA: nonqueued-sender-com-spec{data-element=Value, init-value=0}, provided-interface=VeSCMR_b_Lv2MtrA_TrqAchieved_FA
      VeSCMR_b_Lv2MtrA_TrqAchieved_Vld: nonqueued-sender-com-spec{data-element=Value, init-value=0}, provided-interface=VeSCMR_b_Lv2MtrA_TrqAchieved_Vld
      VeSCMR_M_Lv2MtrA_TrqAchieved_NoAEMD: nonqueued-sender-com-spec{data-element=Value, init-value=0}, provided-interface=VeSCMR_M_Lv2MtrA_TrqAchieved_NoAEMD
      VeSCMR_b_Lv2MtrA_TrqAchieved_NoAEMD_FA: nonqueued-sender-com-spec{data-element=Value, init-value=0}, provided-interface=VeSCMR_b_Lv2MtrA_TrqAchieved_NoAEMD_FA
      VeSCMR_b_Lv2MtrA_TrqAchieved_NoAEMD_Vld: nonqueued-sender-com-spec{data-element=Value, init-value=0}, provided-interface=VeSCMR_b_Lv2MtrA_TrqAchieved_NoAEMD_Vld
      VeSCMR_b_Lv2MtrBFlt_HV_CntctrOpnRq: nonqueued-sender-com-spec{data-element=Value, init-value=0}, provided-interface=VeSCMR_b_Lv2MtrBFlt_HV_CntctrOpnRq
      VeSCMR_b_Lv2MtrBFlt_HV_CntctrOpnRq_FA: nonqueued-sender-com-spec{data-element=Value, init-value=0}, provided-interface=VeSCMR_b_Lv2MtrBFlt_HV_CntctrOpnRq_FA
      VeSCMR_M_Lv2MtrB_MaxTrq: nonqueued-sender-com-spec{data-element=Value, init-value=0}, provided-interface=VeSCMR_M_Lv2MtrB_MaxTrq
      VeSCMR_b_Lv2MtrB_MaxTrq_FA: nonqueued-sender-com-spec{data-element=Value, init-value=0}, provided-interface=VeSCMR_b_Lv2MtrB_MaxTrq_FA
      VeSCMR_M_Lv2MtrB_MinTrq: nonqueued-sender-com-spec{data-element=Value, init-value=0}, provided-interface=VeSCMR_M_Lv2MtrB_MinTrq
      VeSCMR_b_Lv2MtrB_MinTrq_FA: nonqueued-sender-com-spec{data-element=Value, init-value=0}, provided-interface=VeSCMR_b_Lv2MtrB_MinTrq_FA
      VeSCMR_y_Lv2MCPB_MtrIndex_P: nonqueued-sender-com-spec{data-element=Value, init-value=0}, provided-interface=VeSCMR_y_Lv2MCPB_MtrIndex_P
      VeSCMR_b_Lv2MCPB_MtrIndex_P_FA: nonqueued-sender-com-spec{data-element=Value, init-value=0}, provided-interface=VeSCMR_b_Lv2MCPB_MtrIndex_P_FA
      VeSCMR_n_Lv2MtrB_Spd: nonqueued-sender-com-spec{data-element=Value, init-value=0}, provided-interface=VeSCMR_n_Lv2MtrB_Spd
      VeSCMR_b_Lv2MtrB_Spd_FA: nonqueued-sender-com-spec{data-element=Value, init-value=0}, provided-interface=VeSCMR_b_Lv2MtrB_Spd_FA
      VeSCMR_b_Lv2MtrB_Spd_Vld: nonqueued-sender-com-spec{data-element=Value, init-value=0}, provided-interface=VeSCMR_b_Lv2MtrB_Spd_Vld
      VeSCMR_T_Lv2MCPB_Temp: nonqueued-sender-com-spec{data-element=Value, init-value=0}, provided-interface=VeSCMR_T_Lv2MCPB_Temp
      VeSCMR_b_Lv2MCPB_Temp_FA: nonqueued-sender-com-spec{data-element=Value, init-value=0}, provided-interface=VeSCMR_b_Lv2MCPB_Temp_FA
      VeSCMR_M_Lv2MtrB_TrqAchieved: nonqueued-sender-com-spec{data-element=Value, init-value=0}, provided-interface=VeSCMR_M_Lv2MtrB_TrqAchieved
      VeSCMR_b_Lv2MtrB_TrqAchieved_FA: nonqueued-sender-com-spec{data-element=Value, init-value=0}, provided-interface=VeSCMR_b_Lv2MtrB_TrqAchieved_FA
      VeSCMR_b_Lv2MtrB_TrqAchieved_Vld: nonqueued-sender-com-spec{data-element=Value, init-value=0}, provided-interface=VeSCMR_b_Lv2MtrB_TrqAchieved_Vld
      VeSCMR_M_Lv2MtrB_TrqAchieved_NoAEMD: nonqueued-sender-com-spec{data-element=Value, init-value=0}, provided-interface=VeSCMR_M_Lv2MtrB_TrqAchieved_NoAEMD
      VeSCMR_b_Lv2MtrB_TrqAchieved_NoAEMD_FA: nonqueued-sender-com-spec{data-element=Value, init-value=0}, provided-interface=VeSCMR_b_Lv2MtrB_TrqAchieved_NoAEMD_FA
      VeSCMR_b_Lv2MtrB_TrqAchieved_NoAEMD_Vld: nonqueued-sender-com-spec{data-element=Value, init-value=0}, provided-interface=VeSCMR_b_Lv2MtrB_TrqAchieved_NoAEMD_Vld
    require port SRDB_FUNC_FastTEF_StartCheckpoint: client-com-spec=CheckpointReached, required-interface=WdgM_LocalSupervision
    require port SRDB_FUNC_FastTEF_StopCheckpoint: client-com-spec=CheckpointReached, required-interface=WdgM_LocalSupervision
    behavior IB_SRDB_FUNC: data-type-mapping=msADTtoIDTMapping, handle-termination-and-restart=NO-SUPPORT
      timing event Event_FastTEF: start-on-event=SRDB_FUNC_FastTEF, period=0.005
      init event Event_SRDB_FUNC_ac_Init: start-on-event=SRDB_FUNC_ac_Init
      runnable SRDB_FUNC_ac_Init
      runnable SRDB_FUNC_FastTEF
        data-receive-point-by-arguments:
          140 x access:
            IN_VeSR2B_I_BPCM_HV_Current_FD11_Value: accessed-variable=VeSR2B_I_BPCM_HV_Current_FD11.Value
            IN_VeSR2B_I_BPCM_HV_Current_FD5_Value: accessed-variable=VeSR2B_I_BPCM_HV_Current_FD5.Value
            IN_VeSR2B_M_MCPA_MaxTorq_P_FD16_Value: accessed-variable=VeSR2B_M_MCPA_MaxTorq_P_FD16.Value
            IN_VeSR2B_M_MCPA_MaxTorq_P_FD5_Value: accessed-variable=VeSR2B_M_MCPA_MaxTorq_P_FD5.Value
            IN_VeSR2B_M_MCPA_MinTorq_P_FD16_Value: accessed-variable=VeSR2B_M_MCPA_MinTorq_P_FD16.Value
            IN_VeSR2B_M_MCPA_MinTorq_P_FD5_Value: accessed-variable=VeSR2B_M_MCPA_MinTorq_P_FD5.Value
            IN_VeSR2B_M_MCPA_TorqAchved_AEMD_P_FD16_Value: accessed-variable=VeSR2B_M_MCPA_TorqAchved_AEMD_P_FD16.Value
            IN_VeSR2B_M_MCPA_Torque_Achieved_P_FD16_Value: accessed-variable=VeSR2B_M_MCPA_Torque_Achieved_P_FD16.Value
            IN_VeSR2B_M_MCPA_Torque_AchvdPFD5_Value: accessed-variable=VeSR2B_M_MCPA_Torque_AchvdPFD5.Value
            IN_VeSR2B_M_MCPA_TrqAchvdAEMDPFD5_Value: accessed-variable=VeSR2B_M_MCPA_TrqAchvdAEMDPFD5.Value
            IN_VeSR2B_M_MCPB_MaxTorq_P_FD16_Value: accessed-variable=VeSR2B_M_MCPB_MaxTorq_P_FD16.Value
            IN_VeSR2B_M_MCPB_MaxTorq_P_FD5_Value: accessed-variable=VeSR2B_M_MCPB_MaxTorq_P_FD5.Value
            IN_VeSR2B_M_MCPB_MinTorq_P_FD16_Value: accessed-variable=VeSR2B_M_MCPB_MinTorq_P_FD16.Value
            IN_VeSR2B_M_MCPB_MinTorq_P_FD5_Value: accessed-variable=VeSR2B_M_MCPB_MinTorq_P_FD5.Value
            IN_VeSR2B_M_MCPB_TorqAchved_AEMD_P_FD16_Value: accessed-variable=VeSR2B_M_MCPB_TorqAchved_AEMD_P_FD16.Value
            IN_VeSR2B_M_MCPB_Torque_Achieved_P_FD16_Value: accessed-variable=VeSR2B_M_MCPB_Torque_Achieved_P_FD16.Value
            IN_VeSR2B_M_MCPB_TrqAchvd_AEMDPFD5_Value: accessed-variable=VeSR2B_M_MCPB_TrqAchvd_AEMDPFD5.Value
            IN_VeSR2B_M_MCPB_Trq_Achved_P_FD5_Value: accessed-variable=VeSR2B_M_MCPB_Trq_Achved_P_FD5.Value
            IN_VeSR2B_Pct_BPCM_HV_SOC_FD11_Value: accessed-variable=VeSR2B_Pct_BPCM_HV_SOC_FD11.Value
            IN_VeSR2B_Pct_BPCM_HV_SOC_FD5_Value: accessed-variable=VeSR2B_Pct_BPCM_HV_SOC_FD5.Value
            IN_VeSR2B_T_BPCM_HV_Temp_Max_FD11_Value: accessed-variable=VeSR2B_T_BPCM_HV_Temp_Max_FD11.Value
            IN_VeSR2B_T_BPCM_HV_Temp_Max_FD5_Value: accessed-variable=VeSR2B_T_BPCM_HV_Temp_Max_FD5.Value
            IN_VeSR2B_T_BPCM_HV_Temp_Min_FD11_Value: accessed-variable=VeSR2B_T_BPCM_HV_Temp_Min_FD11.Value
            IN_VeSR2B_T_BPCM_HV_Temp_Min_FD5_Value: accessed-variable=VeSR2B_T_BPCM_HV_Temp_Min_FD5.Value
            IN_VeSR2B_T_MCPA_Temp_P_FD16_Value: accessed-variable=VeSR2B_T_MCPA_Temp_P_FD16.Value
            IN_VeSR2B_T_MCPA_Temp_P_FD5_Value: accessed-variable=VeSR2B_T_MCPA_Temp_P_FD5.Value
            IN_VeSR2B_U_APM_HV_V_Fbk_FD11_Value: accessed-variable=VeSR2B_U_APM_HV_V_Fbk_FD11.Value
            IN_VeSR2B_U_APM_HV_V_Fbk_FD5_Value: accessed-variable=VeSR2B_U_APM_HV_V_Fbk_FD5.Value
            IN_VeSR2B_U_APM_LV_V_Fbk_FD11_Value: accessed-variable=VeSR2B_U_APM_LV_V_Fbk_FD11.Value
            IN_VeSR2B_U_APM_LV_V_Fbk_FD5_Value: accessed-variable=VeSR2B_U_APM_LV_V_Fbk_FD5.Value
            IN_VeSR2B_U_BPCM_HV_IntVolt_FD11_Value: accessed-variable=VeSR2B_U_BPCM_HV_IntVolt_FD11.Value
            IN_VeSR2B_U_BPCM_HV_IntVolt_FD5_Value: accessed-variable=VeSR2B_U_BPCM_HV_IntVolt_FD5.Value
            IN_VeSR2B_b_BPCMCntctrsMTOWrn_FD11_Value: accessed-variable=VeSR2B_b_BPCMCntctrsMTOWrn_FD11.Value
            IN_VeSR2B_b_BPCMCntctrsMTOWrn_FD5_Value: accessed-variable=VeSR2B_b_BPCMCntctrsMTOWrn_FD5.Value
            IN_VeSR2B_b_BPCMCntctrsSTOWrn_FD11_Value: accessed-variable=VeSR2B_b_BPCMCntctrsSTOWrn_FD11.Value
            IN_VeSR2B_b_BPCMCntctrsSTOWrn_FD5_Value: accessed-variable=VeSR2B_b_BPCMCntctrsSTOWrn_FD5.Value
            IN_VeSR2B_b_MCPA_HV_CnctrOpnRqPFD5_Value: accessed-variable=VeSR2B_b_MCPA_HV_CnctrOpnRqPFD5.Value
            IN_VeSR2B_b_MCPA_HV_CnctrOpn_Req_P_FD16_Value: accessed-variable=VeSR2B_b_MCPA_HV_CnctrOpn_Req_P_FD16.Value
            IN_VeSR2B_b_MCPA_RPM_V_P_FD16_Value: accessed-variable=VeSR2B_b_MCPA_RPM_V_P_FD16.Value
            IN_VeSR2B_b_MCPA_RPM_V_P_FD5_Value: accessed-variable=VeSR2B_b_MCPA_RPM_V_P_FD5.Value
            IN_VeSR2B_b_MCPA_Torque_Achved_V_P_FD16_Value: accessed-variable=VeSR2B_b_MCPA_Torque_Achved_V_P_FD16.Value
            IN_VeSR2B_b_MCPA_TrqAchvdAEMDVPFD5_Value: accessed-variable=VeSR2B_b_MCPA_TrqAchvdAEMDVPFD5.Value
            IN_VeSR2B_b_MCPA_TrqAchvd_AEMD_V_P_FD16_Value: accessed-variable=VeSR2B_b_MCPA_TrqAchvd_AEMD_V_P_FD16.Value
            IN_VeSR2B_b_MCPA_Trque_AchvdVPFD5_Value: accessed-variable=VeSR2B_b_MCPA_Trque_AchvdVPFD5.Value
            IN_VeSR2B_b_MCPB_HV_CnctrOpnRqPFD5_Value: accessed-variable=VeSR2B_b_MCPB_HV_CnctrOpnRqPFD5.Value
            IN_VeSR2B_b_MCPB_HV_CnctrOpn_Req_P_FD16_Value: accessed-variable=VeSR2B_b_MCPB_HV_CnctrOpn_Req_P_FD16.Value
            IN_VeSR2B_b_MCPB_RPM_V_P_FD16_Value: accessed-variable=VeSR2B_b_MCPB_RPM_V_P_FD16.Value
            IN_VeSR2B_b_MCPB_RPM_V_P_FD5_Value: accessed-variable=VeSR2B_b_MCPB_RPM_V_P_FD5.Value
            IN_VeSR2B_b_MCPB_Torque_Achved_V_P_FD16_Value: accessed-variable=VeSR2B_b_MCPB_Torque_Achved_V_P_FD16.Value
            IN_VeSR2B_b_MCPB_TrqAchvdAEMDVPFD5_Value: accessed-variable=VeSR2B_b_MCPB_TrqAchvdAEMDVPFD5.Value
            IN_VeSR2B_b_MCPB_TrqAchvd_AEMD_V_P_FD16_Value: accessed-variable=VeSR2B_b_MCPB_TrqAchvd_AEMD_V_P_FD16.Value
            IN_VeSR2B_b_MCPB_Trq_Achved_V_PFD5_Value: accessed-variable=VeSR2B_b_MCPB_Trq_Achved_V_PFD5.Value
            IN_VeSR2B_n_MCPA_RPM_P_FD16_Value: accessed-variable=VeSR2B_n_MCPA_RPM_P_FD16.Value
            IN_VeSR2B_n_MCPA_RPM_P_FD5_Value: accessed-variable=VeSR2B_n_MCPA_RPM_P_FD5.Value
            IN_VeSR2B_n_MCPB_RPM_P_FD16_Value: accessed-variable=VeSR2B_n_MCPB_RPM_P_FD16.Value
            IN_VeSR2B_n_MCPB_RPM_P_FD5_Value: accessed-variable=VeSR2B_n_MCPB_RPM_P_FD5.Value
            IN_VeSR2B_y_APM_CtrlSts_Fbk_FD11_Value: accessed-variable=VeSR2B_y_APM_CtrlSts_Fbk_FD11.Value
            IN_VeSR2B_y_APM_CtrlSts_Fbk_FD11_SigSts_Value: accessed-variable=VeSR2B_y_APM_CtrlSts_Fbk_FD11_SigSts.Value
            IN_VeSR2B_y_APM_CtrlSts_Fbk_FD5_Value: accessed-variable=VeSR2B_y_APM_CtrlSts_Fbk_FD5.Value
            IN_VeSR2B_y_APM_CtrlSts_Fbk_FD5_SigSts_Value: accessed-variable=VeSR2B_y_APM_CtrlSts_Fbk_FD5_SigSts.Value
            IN_VeSR2B_y_APM_FailureReason_FD11_Value: accessed-variable=VeSR2B_y_APM_FailureReason_FD11.Value
            IN_VeSR2B_y_APM_FailureReason_FD11_SigSts_Value: accessed-variable=VeSR2B_y_APM_FailureReason_FD11_SigSts.Value
            IN_VeSR2B_y_APM_FailureReason_FD5_Value: accessed-variable=VeSR2B_y_APM_FailureReason_FD5.Value
            IN_VeSR2B_y_APM_FailureReason_FD5_SigSts_Value: accessed-variable=VeSR2B_y_APM_FailureReason_FD5_SigSts.Value
            IN_VeSR2B_y_APM_FailureType_FD11_Value: accessed-variable=VeSR2B_y_APM_FailureType_FD11.Value
            IN_VeSR2B_y_APM_FailureType_FD11_SigSts_Value: accessed-variable=VeSR2B_y_APM_FailureType_FD11_SigSts.Value
            IN_VeSR2B_y_APM_FailureType_FD5_Value: accessed-variable=VeSR2B_y_APM_FailureType_FD5.Value
            IN_VeSR2B_y_APM_FailureType_FD5_SigSts_Value: accessed-variable=VeSR2B_y_APM_FailureType_FD5_SigSts.Value
            IN_VeSR2B_y_APM_HV_V_Fbk_FD11_SigSts_Value: accessed-variable=VeSR2B_y_APM_HV_V_Fbk_FD11_SigSts.Value
            IN_VeSR2B_y_APM_HV_V_Fbk_FD5_SigSts_Value: accessed-variable=VeSR2B_y_APM_HV_V_Fbk_FD5_SigSts.Value
            IN_VeSR2B_y_APM_LV_V_Fbk_FD11_SigSts_Value: accessed-variable=VeSR2B_y_APM_LV_V_Fbk_FD11_SigSts.Value
            IN_VeSR2B_y_APM_LV_V_Fbk_FD5_SigSts_Value: accessed-variable=VeSR2B_y_APM_LV_V_Fbk_FD5_SigSts.Value
            IN_VeSR2B_y_BPCMCntctrsMTOWrn_FD11_SigSts_Value: accessed-variable=VeSR2B_y_BPCMCntctrsMTOWrn_FD11_SigSts.Value
            IN_VeSR2B_y_BPCMCntctrsMTOWrn_FD5_SigSts_Value: accessed-variable=VeSR2B_y_BPCMCntctrsMTOWrn_FD5_SigSts.Value
            IN_VeSR2B_y_BPCMCntctrsSTOWrn_FD11_SigSts_Value: accessed-variable=VeSR2B_y_BPCMCntctrsSTOWrn_FD11_SigSts.Value
            IN_VeSR2B_y_BPCMCntctrsSTOWrn_FD5_SigSts_Value: accessed-variable=VeSR2B_y_BPCMCntctrsSTOWrn_FD5_SigSts.Value
            IN_VeSR2B_y_BPCM_HV_Current_FD11_SigSts_Value: accessed-variable=VeSR2B_y_BPCM_HV_Current_FD11_SigSts.Value
            IN_VeSR2B_y_BPCM_HV_Current_FD5_SigSts_Value: accessed-variable=VeSR2B_y_BPCM_HV_Current_FD5_SigSts.Value
            IN_VeSR2B_y_BPCM_HV_IntVolt_FD11_SigSts_Value: accessed-variable=VeSR2B_y_BPCM_HV_IntVolt_FD11_SigSts.Value
            IN_VeSR2B_y_BPCM_HV_IntVolt_FD5_SigSts_Value: accessed-variable=VeSR2B_y_BPCM_HV_IntVolt_FD5_SigSts.Value
            IN_VeSR2B_y_BPCM_HV_SOC_FD11_SigSts_Value: accessed-variable=VeSR2B_y_BPCM_HV_SOC_FD11_SigSts.Value
            IN_VeSR2B_y_BPCM_HV_SOC_FD5_SigSts_Value: accessed-variable=VeSR2B_y_BPCM_HV_SOC_FD5_SigSts.Value
            IN_VeSR2B_y_BPCM_HV_Temp_Max_FD11_SigSts_Value: accessed-variable=VeSR2B_y_BPCM_HV_Temp_Max_FD11_SigSts.Value
            IN_VeSR2B_y_BPCM_HV_Temp_Max_FD5_SigSts_Value: accessed-variable=VeSR2B_y_BPCM_HV_Temp_Max_FD5_SigSts.Value
            IN_VeSR2B_y_BPCM_HV_Temp_Min_FD11_SigSts_Value: accessed-variable=VeSR2B_y_BPCM_HV_Temp_Min_FD11_SigSts.Value
            IN_VeSR2B_y_BPCM_HV_Temp_Min_FD5_SigSts_Value: accessed-variable=VeSR2B_y_BPCM_HV_Temp_Min_FD5_SigSts.Value
            IN_VeSR2B_y_BPCM_HV_TracBusStsFD11_Value: accessed-variable=VeSR2B_y_BPCM_HV_TracBusStsFD11.Value
            IN_VeSR2B_y_BPCM_HV_TracBusStsFD11_SigSts_Value: accessed-variable=VeSR2B_y_BPCM_HV_TracBusStsFD11_SigSts.Value
            IN_VeSR2B_y_BPCM_HV_TracBusStsFD5_Value: accessed-variable=VeSR2B_y_BPCM_HV_TracBusStsFD5.Value
            IN_VeSR2B_y_BPCM_HV_TracBusStsFD5_SigSts_Value: accessed-variable=VeSR2B_y_BPCM_HV_TracBusStsFD5_SigSts.Value
            IN_VeSR2B_y_MCPA_HV_CnctrOpnRqPFD5_SigSts_Value: accessed-variable=VeSR2B_y_MCPA_HV_CnctrOpnRqPFD5_SigSts.Value
            IN_VeSR2B_y_MCPA_HV_CnctrOpn_Req_P_FD16_SigSts_Value: accessed-variable=VeSR2B_y_MCPA_HV_CnctrOpn_Req_P_FD16_SigSts.Value
            IN_VeSR2B_y_MCPA_MaxTorq_P_FD16_SigSts_Value: accessed-variable=VeSR2B_y_MCPA_MaxTorq_P_FD16_SigSts.Value
            IN_VeSR2B_y_MCPA_MaxTorq_P_FD5_SigSts_Value: accessed-variable=VeSR2B_y_MCPA_MaxTorq_P_FD5_SigSts.Value
            IN_VeSR2B_y_MCPA_MinTorq_P_FD16_SigSts_Value: accessed-variable=VeSR2B_y_MCPA_MinTorq_P_FD16_SigSts.Value
            IN_VeSR2B_y_MCPA_MinTorq_P_FD5_SigSts_Value: accessed-variable=VeSR2B_y_MCPA_MinTorq_P_FD5_SigSts.Value
            IN_VeSR2B_y_MCPA_RPM_P_FD16_SigSts_Value: accessed-variable=VeSR2B_y_MCPA_RPM_P_FD16_SigSts.Value
            IN_VeSR2B_y_MCPA_RPM_P_FD5_SigSts_Value: accessed-variable=VeSR2B_y_MCPA_RPM_P_FD5_SigSts.Value
            IN_VeSR2B_y_MCPA_RPM_V_P_FD16_SigSts_Value: accessed-variable=VeSR2B_y_MCPA_RPM_V_P_FD16_SigSts.Value
            IN_VeSR2B_y_MCPA_RPM_V_P_FD5_SigSts_Value: accessed-variable=VeSR2B_y_MCPA_RPM_V_P_FD5_SigSts.Value
            IN_VeSR2B_y_MCPA_Temp_P_FD16_SigSts_Value: accessed-variable=VeSR2B_y_MCPA_Temp_P_FD16_SigSts.Value
            IN_VeSR2B_y_MCPA_Temp_P_FD5_SigSts_Value: accessed-variable=VeSR2B_y_MCPA_Temp_P_FD5_SigSts.Value
            IN_VeSR2B_y_MCPA_TorqAchved_AEMD_P_FD16_SigSts_Value: accessed-variable=VeSR2B_y_MCPA_TorqAchved_AEMD_P_FD16_SigSts.Value
            IN_VeSR2B_y_MCPA_Torque_Achieved_P_FD16_SigSts_Value: accessed-variable=VeSR2B_y_MCPA_Torque_Achieved_P_FD16_SigSts.Value
            IN_VeSR2B_y_MCPA_Torque_AchvdPFD5_SigSts_Value: accessed-variable=VeSR2B_y_MCPA_Torque_AchvdPFD5_SigSts.Value
            IN_VeSR2B_y_MCPA_Torque_Achved_V_P_FD16_SigSts_Value: accessed-variable=VeSR2B_y_MCPA_Torque_Achved_V_P_FD16_SigSts.Value
            IN_VeSR2B_y_MCPA_TrqAchvdAEMDPFD5_SigSts_Value: accessed-variable=VeSR2B_y_MCPA_TrqAchvdAEMDPFD5_SigSts.Value
            IN_VeSR2B_y_MCPA_TrqAchvdAEMDVPFD5_SigSts_Value: accessed-variable=VeSR2B_y_MCPA_TrqAchvdAEMDVPFD5_SigSts.Value
            IN_VeSR2B_y_MCPA_TrqAchvd_AEMD_V_P_FD16_SigSts_Value: accessed-variable=VeSR2B_y_MCPA_TrqAchvd_AEMD_V_P_FD16_SigSts.Value
            IN_VeSR2B_y_MCPA_Trque_AchvdVPFD5_SigSts_Value: accessed-variable=VeSR2B_y_MCPA_Trque_AchvdVPFD5_SigSts.Value
            IN_VeSR2B_y_MCPB_HV_CnctrOpnRqPFD5_SigSts_Value: accessed-variable=VeSR2B_y_MCPB_HV_CnctrOpnRqPFD5_SigSts.Value
            IN_VeSR2B_y_MCPB_HV_CnctrOpn_Req_P_FD16_SigSts_Value: accessed-variable=VeSR2B_y_MCPB_HV_CnctrOpn_Req_P_FD16_SigSts.Value
            IN_VeSR2B_y_MCPB_MaxTorq_P_FD16_SigSts_Value: accessed-variable=VeSR2B_y_MCPB_MaxTorq_P_FD16_SigSts.Value
            IN_VeSR2B_y_MCPB_MaxTorq_P_FD5_SigSts_Value: accessed-variable=VeSR2B_y_MCPB_MaxTorq_P_FD5_SigSts.Value
            IN_VeSR2B_y_MCPB_MinTorq_P_FD16_SigSts_Value: accessed-variable=VeSR2B_y_MCPB_MinTorq_P_FD16_SigSts.Value
            IN_VeSR2B_y_MCPB_MinTorq_P_FD5_SigSts_Value: accessed-variable=VeSR2B_y_MCPB_MinTorq_P_FD5_SigSts.Value
            IN_VeSR2B_y_MCPB_MtrIndex_P_FD16_Value: accessed-variable=VeSR2B_y_MCPB_MtrIndex_P_FD16.Value
            IN_VeSR2B_y_MCPB_MtrIndex_P_FD16_SigSts_Value: accessed-variable=VeSR2B_y_MCPB_MtrIndex_P_FD16_SigSts.Value
            IN_VeSR2B_y_MCPB_MtrIndex_P_FD5_Value: accessed-variable=VeSR2B_y_MCPB_MtrIndex_P_FD5.Value
            IN_VeSR2B_y_MCPB_MtrIndex_P_FD5_SigSts_Value: accessed-variable=VeSR2B_y_MCPB_MtrIndex_P_FD5_SigSts.Value
            IN_VeSR2B_y_MCPB_RPM_P_FD16_SigSts_Value: accessed-variable=VeSR2B_y_MCPB_RPM_P_FD16_SigSts.Value
            IN_VeSR2B_y_MCPB_RPM_P_FD5_SigSts_Value: accessed-variable=VeSR2B_y_MCPB_RPM_P_FD5_SigSts.Value
            IN_VeSR2B_y_MCPB_RPM_V_P_FD16_SigSts_Value: accessed-variable=VeSR2B_y_MCPB_RPM_V_P_FD16_SigSts.Value
            IN_VeSR2B_y_MCPB_RPM_V_P_FD5_SigSts_Value: accessed-variable=VeSR2B_y_MCPB_RPM_V_P_FD5_SigSts.Value
            IN_VeSR2B_y_MCPB_Temp_P_FD16_Value: accessed-variable=VeSR2B_y_MCPB_Temp_P_FD16.Value
            IN_VeSR2B_y_MCPB_Temp_P_FD16_SigSts_Value: accessed-variable=VeSR2B_y_MCPB_Temp_P_FD16_SigSts.Value
            IN_VeSR2B_y_MCPB_Temp_P_FD5_Value: accessed-variable=VeSR2B_y_MCPB_Temp_P_FD5.Value
            IN_VeSR2B_y_MCPB_Temp_P_FD5_SigSts_Value: accessed-variable=VeSR2B_y_MCPB_Temp_P_FD5_SigSts.Value
            IN_VeSR2B_y_MCPB_TorqAchved_AEMD_P_FD16_SigSts_Value: accessed-variable=VeSR2B_y_MCPB_TorqAchved_AEMD_P_FD16_SigSts.Value
            IN_VeSR2B_y_MCPB_Torque_Achieved_P_FD16_SigSts_Value: accessed-variable=VeSR2B_y_MCPB_Torque_Achieved_P_FD16_SigSts.Value
            IN_VeSR2B_y_MCPB_Torque_Achved_V_P_FD16_SigSts_Value: accessed-variable=VeSR2B_y_MCPB_Torque_Achved_V_P_FD16_SigSts.Value
            IN_VeSR2B_y_MCPB_TrqAchvdAEMDVPFD5_SigSts_Value: accessed-variable=VeSR2B_y_MCPB_TrqAchvdAEMDVPFD5_SigSts.Value
            IN_VeSR2B_y_MCPB_TrqAchvd_AEMDPFD5_SigSts_Value: accessed-variable=VeSR2B_y_MCPB_TrqAchvd_AEMDPFD5_SigSts.Value
            IN_VeSR2B_y_MCPB_TrqAchvd_AEMD_V_P_FD16_SigSts_Value: accessed-variable=VeSR2B_y_MCPB_TrqAchvd_AEMD_V_P_FD16_SigSts.Value
            IN_VeSR2B_y_MCPB_Trq_Achved_P_FD5_SigSts_Value: accessed-variable=VeSR2B_y_MCPB_Trq_Achved_P_FD5_SigSts.Value
            IN_VeSR2B_y_MCPB_Trq_Achved_V_PFD5_SigSts_Value: accessed-variable=VeSR2B_y_MCPB_Trq_Achved_V_PFD5_SigSts.Value
            IN_VeSR2B_y_ProximitySts_FD11_Value: accessed-variable=VeSR2B_y_ProximitySts_FD11.Value
            IN_VeSR2B_y_ProximitySts_FD11_SigSts_Value: accessed-variable=VeSR2B_y_ProximitySts_FD11_SigSts.Value
            IN_VeSR2B_y_ProximitySts_FD5_Value: accessed-variable=VeSR2B_y_ProximitySts_FD5.Value
            IN_VeSR2B_y_ProximitySts_FD5_SigSts_Value: accessed-variable=VeSR2B_y_ProximitySts_FD5_SigSts.Value
        data-send-points:
          66 x access:
            OUT_VeSCMR_b_Lv2MtrCFlt_HV_CntctrOpnRq_Value: accessed-variable=VeSCMR_b_Lv2MtrCFlt_HV_CntctrOpnRq.Value
            OUT_VeSCMR_b_Lv2MtrCFlt_HV_CntctrOpnRq_FA_Value: accessed-variable=VeSCMR_b_Lv2MtrCFlt_HV_CntctrOpnRq_FA.Value
            OUT_VeSCMR_e_Lv2APM_CtrlStsFbk_Value: accessed-variable=VeSCMR_e_Lv2APM_CtrlStsFbk.Value
            OUT_VeSCMR_b_Lv2APM_CtrlStsFbk_FA_Value: accessed-variable=VeSCMR_b_Lv2APM_CtrlStsFbk_FA.Value
            OUT_VeSCMR_e_Lv2APM_FailureReason_Value: accessed-variable=VeSCMR_e_Lv2APM_FailureReason.Value
            OUT_VeSCMR_b_Lv2APM_FailureReason_FA_Value: accessed-variable=VeSCMR_b_Lv2APM_FailureReason_FA.Value
            OUT_VeSCMR_e_Lv2APM_FailureType_Value: accessed-variable=VeSCMR_e_Lv2APM_FailureType.Value
            OUT_VeSCMR_b_Lv2APM_FailureType_FA_Value: accessed-variable=VeSCMR_b_Lv2APM_FailureType_FA.Value
            OUT_VeSCMR_U_Lv2APM_HVBatVlt_Value: accessed-variable=VeSCMR_U_Lv2APM_HVBatVlt.Value
            OUT_VeSCMR_b_Lv2APM_HVBatVlt_FA_Value: accessed-variable=VeSCMR_b_Lv2APM_HVBatVlt_FA.Value
            OUT_VeSCMR_U_Lv2LV_BatVlt_Value: accessed-variable=VeSCMR_U_Lv2LV_BatVlt.Value
            OUT_VeSCMR_b_Lv2LV_BatVlt_FA_Value: accessed-variable=VeSCMR_b_Lv2LV_BatVlt_FA.Value
            OUT_VeSCMR_b_Lv2HV_BatCntctrReq_Value: accessed-variable=VeSCMR_b_Lv2HV_BatCntctrReq.Value
            OUT_VeSCMR_b_Lv2HV_BatCntctrReq_FA_Value: accessed-variable=VeSCMR_b_Lv2HV_BatCntctrReq_FA.Value
            OUT_VeSCMR_b_Lv2HV_BatCntctrOpn_Value: accessed-variable=VeSCMR_b_Lv2HV_BatCntctrOpn.Value
            OUT_VeSCMR_b_Lv2HV_BatCntctrOpn_FA_Value: accessed-variable=VeSCMR_b_Lv2HV_BatCntctrOpn_FA.Value
            OUT_VeSCMR_I_Lv2HV_BatCrnt_Value: accessed-variable=VeSCMR_I_Lv2HV_BatCrnt.Value
            OUT_VeSCMR_b_Lv2HV_BatCrnt_FA_Value: accessed-variable=VeSCMR_b_Lv2HV_BatCrnt_FA.Value
            OUT_VeSCMR_U_Lv2HV_BatVlt_Value: accessed-variable=VeSCMR_U_Lv2HV_BatVlt.Value
            OUT_VeSCMR_b_Lv2HV_BatVlt_FA_Value: accessed-variable=VeSCMR_b_Lv2HV_BatVlt_FA.Value
            OUT_VeSCMR_Pct_Lv2HV_BatSOC_Value: accessed-variable=VeSCMR_Pct_Lv2HV_BatSOC.Value
            OUT_VeSCMR_b_Lv2HV_BatSOC_FA_Value: accessed-variable=VeSCMR_b_Lv2HV_BatSOC_FA.Value
            OUT_VeSCMR_T_Lv2HV_BatModTempMax_Value: accessed-variable=VeSCMR_T_Lv2HV_BatModTempMax.Value
            OUT_VeSCMR_b_Lv2HV_BatModTempMax_FA_Value: accessed-variable=VeSCMR_b_Lv2HV_BatModTempMax_FA.Value
            OUT_VeSCMR_T_Lv2HV_BatModTempMin_Value: accessed-variable=VeSCMR_T_Lv2HV_BatModTempMin.Value
            OUT_VeSCMR_b_Lv2HV_BatModTempMin_FA_Value: accessed-variable=VeSCMR_b_Lv2HV_BatModTempMin_FA.Value
            OUT_VeSCMR_e_Lv2HV_BatCntctrStat_Value: accessed-variable=VeSCMR_e_Lv2HV_BatCntctrStat.Value
            OUT_VeSCMR_b_Lv2HV_BatCntctrStat_FA_Value: accessed-variable=VeSCMR_b_Lv2HV_BatCntctrStat_FA.Value
            OUT_VeSCMR_e_Lv2ProxStat_Value: accessed-variable=VeSCMR_e_Lv2ProxStat.Value
            OUT_VeSCMR_b_Lv2ProxStat_FA_Value: accessed-variable=VeSCMR_b_Lv2ProxStat_FA.Value
            OUT_VeSCMR_b_Lv2MtrAFlt_HV_CntctrOpnRq_Value: accessed-variable=VeSCMR_b_Lv2MtrAFlt_HV_CntctrOpnRq.Value
            OUT_VeSCMR_b_Lv2MtrAFlt_HV_CntctrOpnRq_FA_Value: accessed-variable=VeSCMR_b_Lv2MtrAFlt_HV_CntctrOpnRq_FA.Value
            OUT_VeSCMR_M_Lv2MtrA_MaxTrq_Value: accessed-variable=VeSCMR_M_Lv2MtrA_MaxTrq.Value
            OUT_VeSCMR_b_Lv2MtrA_MaxTrq_FA_Value: accessed-variable=VeSCMR_b_Lv2MtrA_MaxTrq_FA.Value
            OUT_VeSCMR_M_Lv2MtrA_MinTrq_Value: accessed-variable=VeSCMR_M_Lv2MtrA_MinTrq.Value
            OUT_VeSCMR_b_Lv2MtrA_MinTrq_FA_Value: accessed-variable=VeSCMR_b_Lv2MtrA_MinTrq_FA.Value
            OUT_VeSCMR_n_Lv2MtrA_Spd_Value: accessed-variable=VeSCMR_n_Lv2MtrA_Spd.Value
            OUT_VeSCMR_b_Lv2MtrA_Spd_FA_Value: accessed-variable=VeSCMR_b_Lv2MtrA_Spd_FA.Value
            OUT_VeSCMR_b_Lv2MtrA_Spd_Vld_Value: accessed-variable=VeSCMR_b_Lv2MtrA_Spd_Vld.Value
            OUT_VeSCMR_T_Lv2MCPA_Temp_Value: accessed-variable=VeSCMR_T_Lv2MCPA_Temp.Value
            OUT_VeSCMR_b_Lv2MCPA_Temp_FA_Value: accessed-variable=VeSCMR_b_Lv2MCPA_Temp_FA.Value
            OUT_VeSCMR_M_Lv2MtrA_TrqAchieved_Value: accessed-variable=VeSCMR_M_Lv2MtrA_TrqAchieved.Value
            OUT_VeSCMR_b_Lv2MtrA_TrqAchieved_FA_Value: accessed-variable=VeSCMR_b_Lv2MtrA_TrqAchieved_FA.Value
            OUT_VeSCMR_b_Lv2MtrA_TrqAchieved_Vld_Value: accessed-variable=VeSCMR_b_Lv2MtrA_TrqAchieved_Vld.Value
            OUT_VeSCMR_M_Lv2MtrA_TrqAchieved_NoAEMD_Value: accessed-variable=VeSCMR_M_Lv2MtrA_TrqAchieved_NoAEMD.Value
            OUT_VeSCMR_b_Lv2MtrA_TrqAchieved_NoAEMD_FA_Value: accessed-variable=VeSCMR_b_Lv2MtrA_TrqAchieved_NoAEMD_FA.Value
            OUT_VeSCMR_b_Lv2MtrA_TrqAchieved_NoAEMD_Vld_Value: accessed-variable=VeSCMR_b_Lv2MtrA_TrqAchieved_NoAEMD_Vld.Value
            OUT_VeSCMR_b_Lv2MtrBFlt_HV_CntctrOpnRq_Value: accessed-variable=VeSCMR_b_Lv2MtrBFlt_HV_CntctrOpnRq.Value
            OUT_VeSCMR_b_Lv2MtrBFlt_HV_CntctrOpnRq_FA_Value: accessed-variable=VeSCMR_b_Lv2MtrBFlt_HV_CntctrOpnRq_FA.Value
            OUT_VeSCMR_M_Lv2MtrB_MaxTrq_Value: accessed-variable=VeSCMR_M_Lv2MtrB_MaxTrq.Value
            OUT_VeSCMR_b_Lv2MtrB_MaxTrq_FA_Value: accessed-variable=VeSCMR_b_Lv2MtrB_MaxTrq_FA.Value
            OUT_VeSCMR_M_Lv2MtrB_MinTrq_Value: accessed-variable=VeSCMR_M_Lv2MtrB_MinTrq.Value
            OUT_VeSCMR_b_Lv2MtrB_MinTrq_FA_Value: accessed-variable=VeSCMR_b_Lv2MtrB_MinTrq_FA.Value
            OUT_VeSCMR_y_Lv2MCPB_MtrIndex_P_Value: accessed-variable=VeSCMR_y_Lv2MCPB_MtrIndex_P.Value
            OUT_VeSCMR_b_Lv2MCPB_MtrIndex_P_FA_Value: accessed-variable=VeSCMR_b_Lv2MCPB_MtrIndex_P_FA.Value
            OUT_VeSCMR_n_Lv2MtrB_Spd_Value: accessed-variable=VeSCMR_n_Lv2MtrB_Spd.Value
            OUT_VeSCMR_b_Lv2MtrB_Spd_FA_Value: accessed-variable=VeSCMR_b_Lv2MtrB_Spd_FA.Value
            OUT_VeSCMR_b_Lv2MtrB_Spd_Vld_Value: accessed-variable=VeSCMR_b_Lv2MtrB_Spd_Vld.Value
            OUT_VeSCMR_T_Lv2MCPB_Temp_Value: accessed-variable=VeSCMR_T_Lv2MCPB_Temp.Value
            OUT_VeSCMR_b_Lv2MCPB_Temp_FA_Value: accessed-variable=VeSCMR_b_Lv2MCPB_Temp_FA.Value
            OUT_VeSCMR_M_Lv2MtrB_TrqAchieved_Value: accessed-variable=VeSCMR_M_Lv2MtrB_TrqAchieved.Value
            OUT_VeSCMR_b_Lv2MtrB_TrqAchieved_FA_Value: accessed-variable=VeSCMR_b_Lv2MtrB_TrqAchieved_FA.Value
            OUT_VeSCMR_b_Lv2MtrB_TrqAchieved_Vld_Value: accessed-variable=VeSCMR_b_Lv2MtrB_TrqAchieved_Vld.Value
            OUT_VeSCMR_M_Lv2MtrB_TrqAchieved_NoAEMD_Value: accessed-variable=VeSCMR_M_Lv2MtrB_TrqAchieved_NoAEMD.Value
            OUT_VeSCMR_b_Lv2MtrB_TrqAchieved_NoAEMD_FA_Value: accessed-variable=VeSCMR_b_Lv2MtrB_TrqAchieved_NoAEMD_FA.Value
            OUT_VeSCMR_b_Lv2MtrB_TrqAchieved_NoAEMD_Vld_Value: accessed-variable=VeSCMR_b_Lv2MtrB_TrqAchieved_NoAEMD_Vld.Value
        sync call SC_SRDB_FUNC_FastTEF_StartCheckpoint_CheckpointReached: operation=SRDB_FUNC_FastTEF_StartCheckpoint.CheckpointReached, timeout=1E-06
        sync call SC_SRDB_FUNC_FastTEF_StopCheckpoint_CheckpointReached: operation=SRDB_FUNC_FastTEF_StopCheckpoint.CheckpointReached, timeout=1E-06
      variation point proxy VrntSRDB_SGCPHVCnctrOpnReqPVeSCMRLv2MtrCFlt_HVCntctrOpnRq: category=CONDITION, condition-access=0
      variation point proxy VrntSRDB_SGCPHVCnctrOpnReqPVeSCMRLv2MtrCFlt_HVCntctrOpnRq_FA: category=CONDITION, condition-access=0
